VERSION "1.3"

NS_ :

BS_:
BU_: AMK_Inverter

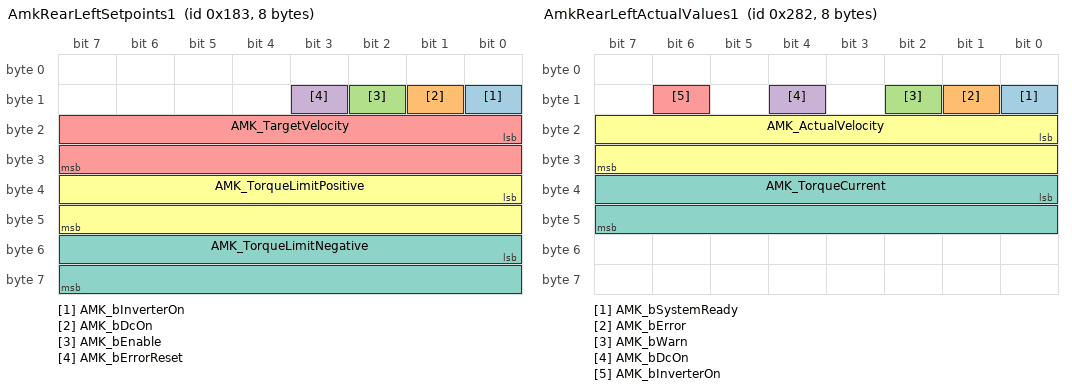
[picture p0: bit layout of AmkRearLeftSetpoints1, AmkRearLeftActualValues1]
BO_ 387 AmkRearLeftSetpoints1: 8 AMK_Inverter
 SG_ AMK_bInverterOn : 8|1@1+ (1,0) [0|1] "" Vector_XXX
 SG_ AMK_bDcOn : 9|1@1+ (1,0) [0|1] "" Vector_XXX
 SG_ AMK_bEnable : 10|1@1+ (1,0) [0|1] "" Vector_XXX
 SG_ AMK_bErrorReset : 11|1@1+ (1,0) [0|1] "" Vector_XXX
 SG_ AMK_TargetVelocity : 16|16@1- (1,0) [-32768|32767] "rpm" Vector_XXX
 SG_ AMK_TorqueLimitPositive : 32|16@1- (1,0) [0|32767] "raw" Vector_XXX
 SG_ AMK_TorqueLimitNegative : 48|16@1- (1,0) [-32768|0] "raw" Vector_XXX

BO_ 642 AmkRearLeftActualValues1: 8 AMK_Inverter
 SG_ AMK_bSystemReady : 8|1@1+ (1,0) [0|1] "" Vector_XXX
 SG_ AMK_bError : 9|1@1+ (1,0) [0|1] "" Vector_XXX
 SG_ AMK_bWarn : 10|1@1+ (1,0) [0|1] "" Vector_XXX
 SG_ AMK_bDcOn : 12|1@1+ (1,0) [0|1] "" Vector_XXX
 SG_ AMK_bInverterOn : 14|1@1+ (1,0) [0|1] "" Vector_XXX
 SG_ AMK_ActualVelocity : 16|16@1- (1,0) [-32768|32767] "rpm" Vector_XXX
 SG_ AMK_TorqueCurrent : 32|16@1- (1,0) [-32768|32767] "raw" Vector_XXX

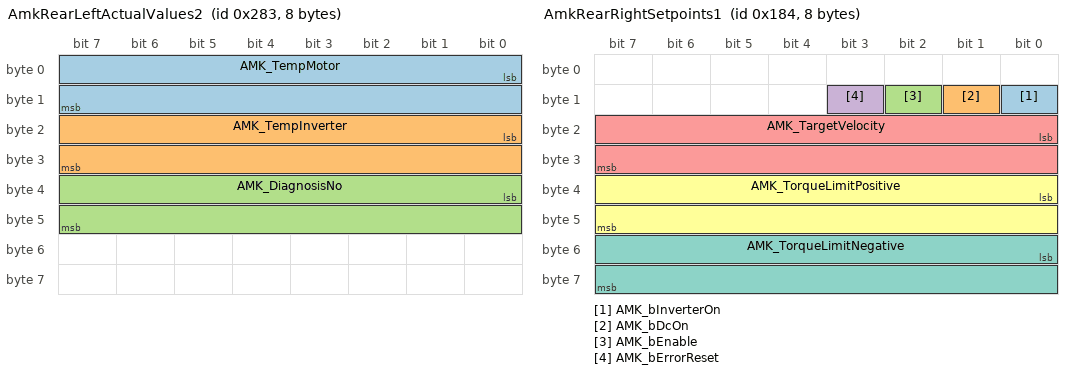
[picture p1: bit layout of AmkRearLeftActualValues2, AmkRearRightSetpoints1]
BO_ 643 AmkRearLeftActualValues2: 8 AMK_Inverter
 SG_ AMK_TempMotor : 0|16@1- (0.1,0) [-3276.8|3276.7] "degC" Vector_XXX
 SG_ AMK_TempInverter : 16|16@1- (0.1,0) [-3276.8|3276.7] "degC" Vector_XXX
 SG_ AMK_DiagnosisNo : 32|16@1+ (1,0) [0|65535] "" Vector_XXX

BO_ 388 AmkRearRightSetpoints1: 8 AMK_Inverter
 SG_ AMK_bInverterOn : 8|1@1+ (1,0) [0|1] "" Vector_XXX
 SG_ AMK_bDcOn : 9|1@1+ (1,0) [0|1] "" Vector_XXX
 SG_ AMK_bEnable : 10|1@1+ (1,0) [0|1] "" Vector_XXX
 SG_ AMK_bErrorReset : 11|1@1+ (1,0) [0|1] "" Vector_XXX
 SG_ AMK_TargetVelocity : 16|16@1- (1,0) [-32768|32767] "rpm" Vector_XXX
 SG_ AMK_TorqueLimitPositive : 32|16@1- (1,0) [0|32767] "raw" Vector_XXX
 SG_ AMK_TorqueLimitNegative : 48|16@1- (1,0) [-32768|0] "raw" Vector_XXX

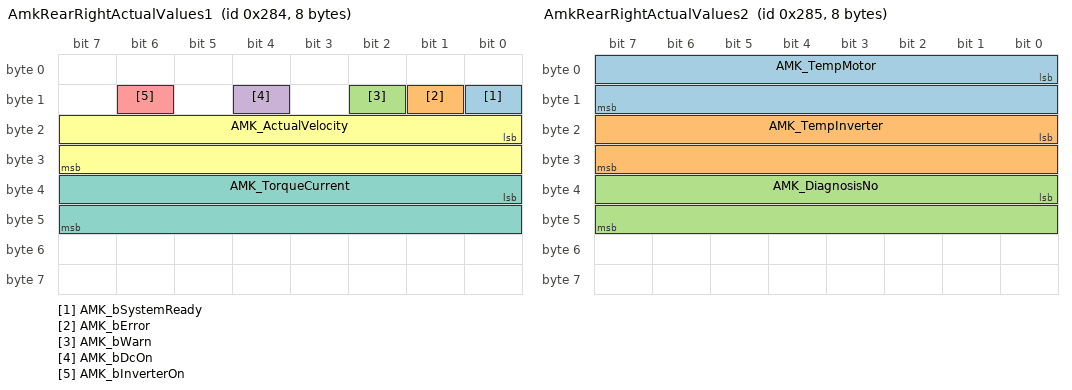
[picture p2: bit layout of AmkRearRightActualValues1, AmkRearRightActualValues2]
BO_ 644 AmkRearRightActualValues1: 8 AMK_Inverter
 SG_ AMK_bSystemReady : 8|1@1+ (1,0) [0|1] "" Vector_XXX
 SG_ AMK_bError : 9|1@1+ (1,0) [0|1] "" Vector_XXX
 SG_ AMK_bWarn : 10|1@1+ (1,0) [0|1] "" Vector_XXX
 SG_ AMK_bDcOn : 12|1@1+ (1,0) [0|1] "" Vector_XXX
 SG_ AMK_bInverterOn : 14|1@1+ (1,0) [0|1] "" Vector_XXX
 SG_ AMK_ActualVelocity : 16|16@1- (1,0) [-32768|32767] "rpm" Vector_XXX
 SG_ AMK_TorqueCurrent : 32|16@1- (1,0) [-32768|32767] "raw" Vector_XXX

BO_ 645 AmkRearRightActualValues2: 8 AMK_Inverter
 SG_ AMK_TempMotor : 0|16@1- (0.1,0) [-3276.8|3276.7] "degC" Vector_XXX
 SG_ AMK_TempInverter : 16|16@1- (0.1,0) [-3276.8|3276.7] "degC" Vector_XXX
 SG_ AMK_DiagnosisNo : 32|16@1+ (1,0) [0|65535] "" Vector_XXX

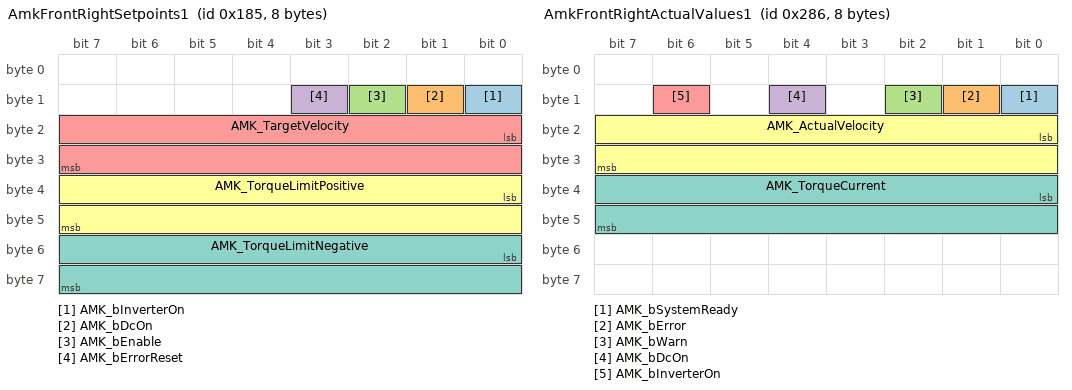
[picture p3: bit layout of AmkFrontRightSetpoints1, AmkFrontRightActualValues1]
BO_ 389 AmkFrontRightSetpoints1: 8 AMK_Inverter
 SG_ AMK_bInverterOn : 8|1@1+ (1,0) [0|1] "" Vector_XXX
 SG_ AMK_bDcOn : 9|1@1+ (1,0) [0|1] "" Vector_XXX
 SG_ AMK_bEnable : 10|1@1+ (1,0) [0|1] "" Vector_XXX
 SG_ AMK_bErrorReset : 11|1@1+ (1,0) [0|1] "" Vector_XXX
 SG_ AMK_TargetVelocity : 16|16@1- (1,0) [-32768|32767] "rpm" Vector_XXX
 SG_ AMK_TorqueLimitPositive : 32|16@1- (1,0) [0|32767] "raw" Vector_XXX
 SG_ AMK_TorqueLimitNegative : 48|16@1- (1,0) [-32768|0] "raw" Vector_XXX

BO_ 646 AmkFrontRightActualValues1: 8 AMK_Inverter
 SG_ AMK_bSystemReady : 8|1@1+ (1,0) [0|1] "" Vector_XXX
 SG_ AMK_bError : 9|1@1+ (1,0) [0|1] "" Vector_XXX
 SG_ AMK_bWarn : 10|1@1+ (1,0) [0|1] "" Vector_XXX
 SG_ AMK_bDcOn : 12|1@1+ (1,0) [0|1] "" Vector_XXX
 SG_ AMK_bInverterOn : 14|1@1+ (1,0) [0|1] "" Vector_XXX
 SG_ AMK_ActualVelocity : 16|16@1- (1,0) [-32768|32767] "rpm" Vector_XXX
 SG_ AMK_TorqueCurrent : 32|16@1- (1,0) [-32768|32767] "raw" Vector_XXX

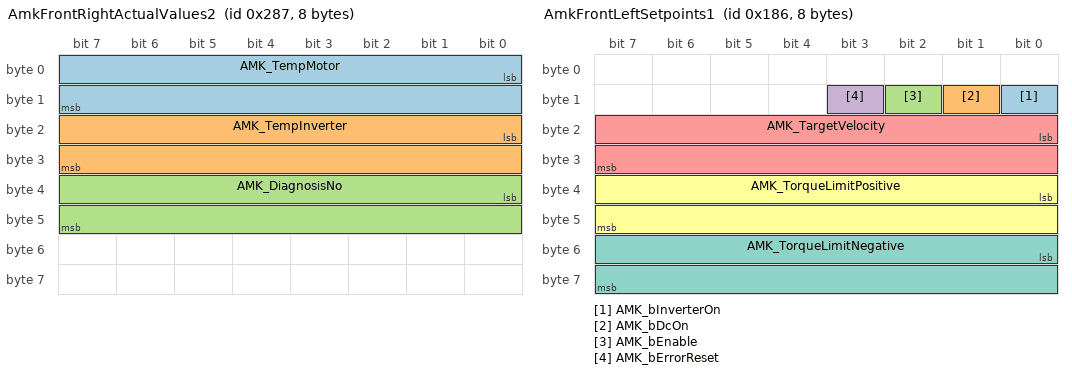
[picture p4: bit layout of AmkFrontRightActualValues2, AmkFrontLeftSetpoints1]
BO_ 647 AmkFrontRightActualValues2: 8 AMK_Inverter
 SG_ AMK_TempMotor : 0|16@1- (0.1,0) [-3276.8|3276.7] "degC" Vector_XXX
 SG_ AMK_TempInverter : 16|16@1- (0.1,0) [-3276.8|3276.7] "degC" Vector_XXX
 SG_ AMK_DiagnosisNo : 32|16@1+ (1,0) [0|65535] "" Vector_XXX

BO_ 390 AmkFrontLeftSetpoints1: 8 AMK_Inverter
 SG_ AMK_bInverterOn : 8|1@1+ (1,0) [0|1] "" Vector_XXX
 SG_ AMK_bDcOn : 9|1@1+ (1,0) [0|1] "" Vector_XXX
 SG_ AMK_bEnable : 10|1@1+ (1,0) [0|1] "" Vector_XXX
 SG_ AMK_bErrorReset : 11|1@1+ (1,0) [0|1] "" Vector_XXX
 SG_ AMK_TargetVelocity : 16|16@1- (1,0) [-32768|32767] "rpm" Vector_XXX
 SG_ AMK_TorqueLimitPositive : 32|16@1- (1,0) [0|32767] "raw" Vector_XXX
 SG_ AMK_TorqueLimitNegative : 48|16@1- (1,0) [-32768|0] "raw" Vector_XXX

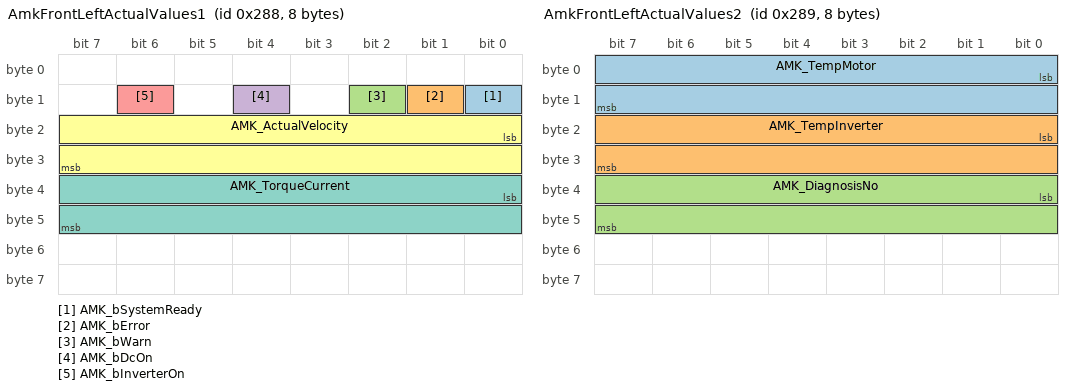
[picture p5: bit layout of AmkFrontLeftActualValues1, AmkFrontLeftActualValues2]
BO_ 648 AmkFrontLeftActualValues1: 8 AMK_Inverter
 SG_ AMK_bSystemReady : 8|1@1+ (1,0) [0|1] "" Vector_XXX
 SG_ AMK_bError : 9|1@1+ (1,0) [0|1] "" Vector_XXX
 SG_ AMK_bWarn : 10|1@1+ (1,0) [0|1] "" Vector_XXX
 SG_ AMK_bDcOn : 12|1@1+ (1,0) [0|1] "" Vector_XXX
 SG_ AMK_bInverterOn : 14|1@1+ (1,0) [0|1] "" Vector_XXX
 SG_ AMK_ActualVelocity : 16|16@1- (1,0) [-32768|32767] "rpm" Vector_XXX
 SG_ AMK_TorqueCurrent : 32|16@1- (1,0) [-32768|32767] "raw" Vector_XXX

BO_ 649 AmkFrontLeftActualValues2: 8 AMK_Inverter
 SG_ AMK_TempMotor : 0|16@1- (0.1,0) [-3276.8|3276.7] "degC" Vector_XXX
 SG_ AMK_TempInverter : 16|16@1- (0.1,0) [-3276.8|3276.7] "degC" Vector_XXX
 SG_ AMK_DiagnosisNo : 32|16@1+ (1,0) [0|65535] "" Vector_XXX

BA_DEF_ BO_ "GenMsgCycleTime" INT 0 65535;
BA_ "GenMsgCycleTime" BO_ 387 5;
BA_ "GenMsgCycleTime" BO_ 642 5;
BA_ "GenMsgCycleTime" BO_ 643 5;
BA_ "GenMsgCycleTime" BO_ 388 5;
BA_ "GenMsgCycleTime" BO_ 644 5;
BA_ "GenMsgCycleTime" BO_ 645 5;
BA_ "GenMsgCycleTime" BO_ 389 5;
BA_ "GenMsgCycleTime" BO_ 646 5;
BA_ "GenMsgCycleTime" BO_ 647 5;
BA_ "GenMsgCycleTime" BO_ 390 5;
BA_ "GenMsgCycleTime" BO_ 648 5;
BA_ "GenMsgCycleTime" BO_ 649 5;
